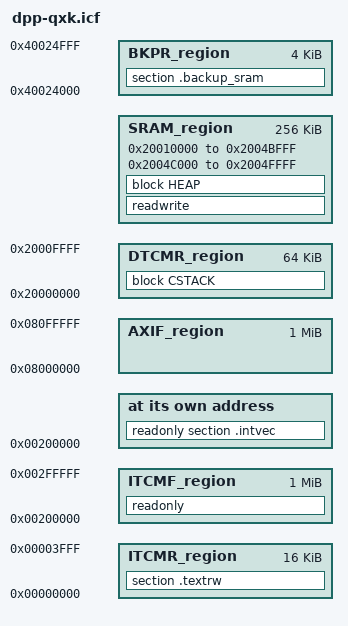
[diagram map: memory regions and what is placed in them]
/*###ICF### Section handled by ICF editor, don't touch! ****/
/*-Editor annotation file-*/
/* IcfEditorFile="$TOOLKIT_DIR$\config\linker\ST\IcfEditor\stm32f7xx.xml" */
/*-Specials-*/
define symbol __ICFEDIT_intvec_start__ = 0x00200000;
/*-Memory Regions-*/
define symbol __ICFEDIT_region_ITCMF_start__ = 0x00200000;
define symbol __ICFEDIT_region_ITCMF_end__   = 0x002FFFFF;
define symbol __ICFEDIT_region_AXIF_start__  = 0x08000000;
define symbol __ICFEDIT_region_AXIF_end__    = 0x080FFFFF;
define symbol __ICFEDIT_region_FMC11_start__ = 0x0;
define symbol __ICFEDIT_region_FMC11_end__   = 0x0;
define symbol __ICFEDIT_region_FMC12_start__ = 0x0;
define symbol __ICFEDIT_region_FMC12_end__   = 0x0;
define symbol __ICFEDIT_region_FMC13_start__ = 0x0;
define symbol __ICFEDIT_region_FMC13_end__   = 0x0;
define symbol __ICFEDIT_region_FMC14_start__ = 0x0;
define symbol __ICFEDIT_region_FMC14_end__   = 0x0;
define symbol __ICFEDIT_region_NAND_start__  = 0x0;
define symbol __ICFEDIT_region_NAND_end__    = 0x0;
define symbol __ICFEDIT_region_QSPI_start__  = 0x0;
define symbol __ICFEDIT_region_QSPI_end__    = 0x0;
define symbol __ICFEDIT_region_ITCMR_start__ = 0x00000000;
define symbol __ICFEDIT_region_ITCMR_end__   = 0x00003FFF;
define symbol __ICFEDIT_region_DTCMR_start__ = 0x20000000;
define symbol __ICFEDIT_region_DTCMR_end__   = 0x2000FFFF;
define symbol __ICFEDIT_region_SRAM1_start__ = 0x20010000;
define symbol __ICFEDIT_region_SRAM1_end__   = 0x2004BFFF;
define symbol __ICFEDIT_region_SRAM2_start__ = 0x2004C000;
define symbol __ICFEDIT_region_SRAM2_end__   = 0x2004FFFF;
define symbol __ICFEDIT_region_BKPR_start__  = 0x40024000;
define symbol __ICFEDIT_region_BKPR_end__    = 0x40024FFF;
define symbol __ICFEDIT_region_SDR1_start__  = 0x0;
define symbol __ICFEDIT_region_SDR1_end__    = 0x0;
define symbol __ICFEDIT_region_SDR2_start__  = 0x0;
define symbol __ICFEDIT_region_SDR2_end__    = 0x0;
/*-Sizes-*/
define symbol __ICFEDIT_size_cstack__ = 2048;
define symbol __ICFEDIT_size_heap__   = 0;
/**** End of ICF editor section. ###ICF###*/

define memory mem with size = 4G;
define region ITCMF_region  =   mem:[from __ICFEDIT_region_ITCMF_start__ to __ICFEDIT_region_ITCMF_end__];
define region AXIF_region   =   mem:[from __ICFEDIT_region_AXIF_start__  to __ICFEDIT_region_AXIF_end__ ];
define region FMC1_region   =   mem:[from __ICFEDIT_region_FMC11_start__ to __ICFEDIT_region_FMC11_end__]
                              | mem:[from __ICFEDIT_region_FMC12_start__ to __ICFEDIT_region_FMC12_end__]
                              | mem:[from __ICFEDIT_region_FMC13_start__ to __ICFEDIT_region_FMC13_end__]
                              | mem:[from __ICFEDIT_region_FMC14_start__ to __ICFEDIT_region_FMC14_end__];
define region NAND_region   =   mem:[from __ICFEDIT_region_NAND_start__  to __ICFEDIT_region_NAND_end__ ];
define region QSPI_region   =   mem:[from __ICFEDIT_region_QSPI_start__  to __ICFEDIT_region_QSPI_end__ ];
define region ITCMR_region  =   mem:[from __ICFEDIT_region_ITCMR_start__ to __ICFEDIT_region_ITCMR_end__];
define region DTCMR_region  =   mem:[from __ICFEDIT_region_DTCMR_start__ to __ICFEDIT_region_DTCMR_end__];
define region SRAM_region   =   mem:[from __ICFEDIT_region_SRAM1_start__ to __ICFEDIT_region_SRAM1_end__]
                              | mem:[from __ICFEDIT_region_SRAM2_start__ to __ICFEDIT_region_SRAM2_end__];
define region BKPR_region   =   mem:[from __ICFEDIT_region_BKPR_start__  to __ICFEDIT_region_BKPR_end__ ];
define region SDR_region    =   mem:[from __ICFEDIT_region_SDR1_start__  to __ICFEDIT_region_SDR1_end__ ]
                              | mem:[from __ICFEDIT_region_SDR2_start__  to __ICFEDIT_region_SDR2_end__ ];

define block CSTACK    with alignment = 8, size = __ICFEDIT_size_cstack__   { };
define block HEAP      with alignment = 8, size = __ICFEDIT_size_heap__     { };

initialize by copy { readwrite };
//initialize by copy with packing = none { section __DLIB_PERTHREAD }; // Required in a multi-threaded application
do not initialize  { section .noinit };

place at address mem:__ICFEDIT_intvec_start__ { readonly section .intvec };

place in ITCMF_region  { readonly };
place in QSPI_region   { readonly section application_specific_ro };
place in ITCMR_region  { section .textrw };
place in DTCMR_region  { block CSTACK };
place in SRAM_region   { readwrite, block HEAP };
place in BKPR_region   { section .backup_sram };
place in SDR_region    { readwrite section application_specific_rw };
